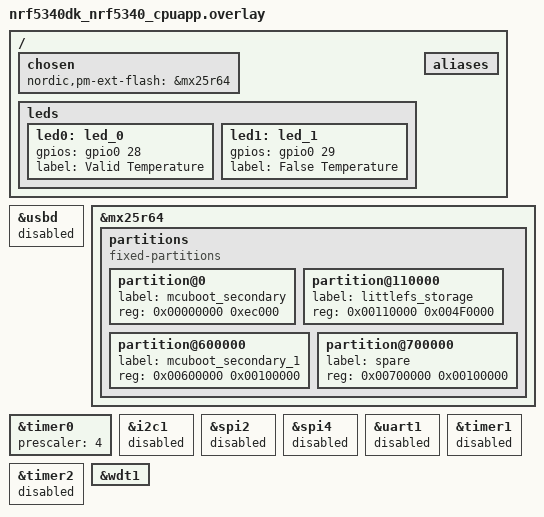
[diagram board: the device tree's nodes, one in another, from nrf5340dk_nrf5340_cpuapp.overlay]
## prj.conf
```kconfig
# Increased stack due to settings API usage
CONFIG_SYSTEM_WORKQUEUE_STACK_SIZE=2048

CONFIG_BT=y
CONFIG_BT_DEBUG_LOG=y
CONFIG_BT_SMP=y
CONFIG_BT_SIGNING=y
CONFIG_BT_PERIPHERAL=y
CONFIG_BT_DIS=y
CONFIG_BT_ATT_PREPARE_COUNT=5
CONFIG_BT_BAS=y
CONFIG_BT_HRS=y
CONFIG_BT_IAS=y
CONFIG_BT_PRIVACY=y
CONFIG_BT_DEVICE_NAME="Zephyr Peripheral Sample Long Name"
CONFIG_BT_DEVICE_APPEARANCE=833
CONFIG_BT_DEVICE_NAME_DYNAMIC=y
CONFIG_BT_DEVICE_NAME_MAX=65

CONFIG_BT_KEYS_OVERWRITE_OLDEST=y
# CONFIG_BT_SETTINGS=y
CONFIG_FLASH=y
CONFIG_FLASH_MAP=y
CONFIG_FLASH_PAGE_LAYOUT=y

CONFIG_FILE_SYSTEM=y
CONFIG_FILE_SYSTEM_LITTLEFS=y
CONFIG_NVS=y
# CONFIG_SETTINGS=y

# Enable bonding of Bluetooth peers.
# CONFIG_SETTINGS_FS_FILE="/lfs/bt/settings"
# CONFIG_SETTINGS_FS_DIR="/lfs/bt"

CONFIG_BT_HCI_VS=y                          # Vendor-specific commands
CONFIG_BT_HCI_VS_EXT=y                      # Extended vendor-specific

CONFIG_NORDIC_QSPI_NOR=y
CONFIG_NORDIC_QSPI_NOR_FLASH_LAYOUT_PAGE_SIZE=4096
CONFIG_NORDIC_QSPI_NOR_STACK_WRITE_BUFFER_SIZE=4
#CONFIG_PM_EXTERNAL_FLASH=y
#CONFIG_PM_EXTERNAL_FLASH_DEV_NAME="MX25R64"
#CONFIG_PM_EXTERNAL_FLASH_BASE=0x0
#CONFIG_PM_EXTERNAL_FLASH_SIZE=0x800000
#CONFIG_SPI_NOR_IDLE_IN_DPD=y

#CONFIG_NVS=y
CONFIG_MPU_ALLOW_FLASH_WRITE=y

#https://devzone.nordicsemi.com/f/nordic-q-a/76585/extends-the-mtu-size-in-latest-zephyr
CONFIG_BT_L2CAP_TX_MTU=498
CONFIG_BT_BUF_ACL_RX_SIZE=502
CONFIG_BT_BUF_ACL_TX_SIZE=502
CONFIG_BT_CTLR_DATA_LENGTH_MAX=251

CONFIG_BT_PERIPHERAL_PREF_MIN_INT=50
CONFIG_BT_PERIPHERAL_PREF_MAX_INT=250
CONFIG_BT_PERIPHERAL_PREF_LATENCY=0
CONFIG_BT_PERIPHERAL_PREF_TIMEOUT=600

# Appearance indicates the type of device (phone, computer, thermometer, etc).
# Set it to "Energy Harvesting Switch" 0x04CB (1227)
# https://specificationrefs.bluetooth.com/assigned-values/Appearance%20Values.pdf
CONFIG_BT_DEVICE_APPEARANCE=1227

# Configure the cryptography backends to use.
# WARNING: Don't turn this on!  It consumes >150ms of startup time!  Why?!?
#CONFIG_NORDIC_SECURITY_BACKEND=y
#CONFIG_CC3XX_BACKEND=y
##CONFIG_MBEDTLS_VANILLA_BACKEND=n
#CONFIG_OBERON_BACKEND=n

# Enable MCUboot and MCUmgr to support DFU firmware updates.
CONFIG_BOOTLOADER_MCUBOOT=y
CONFIG_MCUMGR=y
CONFIG_MCUMGR_CMD_IMG_MGMT=y
CONFIG_MCUMGR_CMD_OS_MGMT=y
CONFIG_MCUMGR_CMD_STAT_MGMT=y
CONFIG_MCUMGR_SMP_BT=y
#CONFIG_LOG=y
#CONFIG_MCUBOOT_UTIL_LOG_LEVEL_WRN=y
#CONFIG_LOG_DEFAULT_LEVEL=4

# From Overlay.bt-conf file
# Allow for large Bluetooth data packets.
# Enable the Bluetooth mcumgr transport (unauthenticated).
CONFIG_MCUMGR_SMP_BT_AUTHEN=n
CONFIG_MCUMGR_SMP_BT_CONN_PARAM_CONTROL=y

# Enable the mcumgr Packet Reassembly feature over Bluetooth and its configuration dependencies.
# MCUmgr buffer size is optimized to fit one SMP packet divided into five Bluetooth Write Commands,
# transmitted with the maximum possible MTU value: 498 bytes.
CONFIG_MCUMGR_SMP_REASSEMBLY_BT=y
CONFIG_MCUMGR_BUF_SIZE=2475
CONFIG_OS_MGMT_MCUMGR_PARAMS=y
# Enable file system commands
CONFIG_MCUMGR_CMD_FS_MGMT=y
# Enable the storage erase command.
CONFIG_MCUMGR_GRP_ZEPHYR_BASIC=y
CONFIG_MCUMGR_GRP_BASIC_CMD_STORAGE_ERASE=y
# Erase slot 1 in parts as and when FW is copied.
CONFIG_IMG_ERASE_PROGRESSIVELY=y
# Disable Bluetooth ping support
CONFIG_BT_CTLR_LE_PING=n

# The following configurations are required to support simultaneous multi image update
CONFIG_PCD_APP=y
CONFIG_UPDATEABLE_IMAGE_NUMBER=2
# CONFIG_BOOT_UPGRADE_ONLY=y
CONFIG_BT_RPMSG=y
```

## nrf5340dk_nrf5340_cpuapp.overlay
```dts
/* Shift the console to USB - FIXME: remove this later */
/*
/ {
    chosen {
        zephyr,console = &cdc_acm_uart0;
    };
};
&zephyr_udc0 {
        cdc_acm_uart0: cdc_acm_uart0 {
                compatible = "zephyr,cdc-acm-uart";
                label = "CDC_ACM_0";
        };
};*/
&usbd {
    status = "disabled";
};

/* Define the partitions in the external NOR flash memory chip */
&mx25r64 {

    partitions {
        compatible = "fixed-partitions";
        #address-cells = <1>;
        #size-cells = <1>;

        /* First 1Mb is for a second program image for MCUboot */
        partition@0 {
            label = "mcuboot_secondary";
            reg = <0x00000000 0xec000>;
        };


        /* 5056kB partition for the littlefs filesystem */
        partition@110000 {
            label = "littlefs_storage";
            reg = <0x00110000 0x004F0000>;
        };

        /* 1024kB spare partition */
        partition@600000 {
            label = "mcuboot_secondary_1";
            reg = <0x00600000 0x00100000>;
        };

        /* 1024kB spare partition */
        partition@700000 {
            label = "spare";
            reg = <0x00700000 0x00100000>;
        };
    };

};


/* Change the prescaler for timer0 so that it operates off the
   lower power 1MHz clock instead of the 16MHz clock. */
&timer0 {
    prescaler = <4>; /* prescaler of 2^4 = divide by 16 */
};

/* Disable peripherals that we don't need */
&i2c1 {
    status = "disabled";
};
&spi2 {
    status = "disabled";
};
&spi4 {
    status = "disabled";
    /delete-property/ cs-gpios;
};
&uart1 {
    status = "disabled";
};
&timer1 {
    status = "disabled";
};
&timer2 {
    status = "disabled";
};
&wdt1 {
    status = "okay";
};
/* Disable forwarding of UART pins to the network core */
/delete-node/ &gpio_fwd;

/ {
    /* Use paritition manager to manage the layout of external NOR flash */
    chosen {
        nordic,pm-ext-flash = &mx25r64;
    };

    /* Redefine the LED's */
    leds {
        /delete-node/ led0;
        /delete-node/ led1;

        led0: led_0 {
                gpios = <&gpio0 28 GPIO_ACTIVE_HIGH>;
                label = "Valid Temperature";
        };
        led1: led_1 {
                gpios = <&gpio0 29 GPIO_ACTIVE_HIGH>;
                label = "False Temperature";
        };
    };

    aliases {
        /* Remove unnecessary aliases */
        /delete-property/ led2;
        /delete-property/ led3;
        /delete-property/ sw0;
        /delete-property/ sw1;
        /delete-property/ sw2;
        /delete-property/ sw3;
        /delete-property/ pwm-led0;
    };

};
```

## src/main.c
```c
/* main.c - Application main entry point */

/*
 * Copyright (c) 2015-2016 Intel Corporation
 *
 * SPDX-License-Identifier: Apache-2.0
 */

#include <zephyr/types.h>
#include <stddef.h>
#include <string.h>
#include <errno.h>
#include <zephyr/sys/printk.h>
#include <zephyr/sys/byteorder.h>
#include <zephyr/kernel.h>

#include <zephyr/settings/settings.h>

#include <zephyr/bluetooth/bluetooth.h>
#include <zephyr/bluetooth/hci.h>
#include <zephyr/bluetooth/conn.h>
#include <zephyr/bluetooth/uuid.h>
#include <zephyr/bluetooth/gatt.h>
#include <zephyr/bluetooth/services/bas.h>
#include <zephyr/bluetooth/services/hrs.h>
#include <zephyr/bluetooth/services/ias.h>

#include <zephyr/mgmt/mcumgr/smp_bt.h>
#if defined(CONFIG_BT_HCI_VS_EXT)
#include <zephyr/bluetooth/bluetooth.h>
#include <zephyr/bluetooth/hci.h>
#include <zephyr/bluetooth/hci_vs.h>
#endif
// #include "filesystem.h"
#include "cts.h"
// #include "filesystem.h"
#ifdef CONFIG_MCUMGR_CMD_OS_MGMT
#include "os_mgmt/os_mgmt.h"
#endif
#ifdef CONFIG_MCUMGR_CMD_IMG_MGMT
#include "img_mgmt/img_mgmt.h"
#endif
#ifdef CONFIG_MCUMGR_CMD_STAT_MGMT
#include "stat_mgmt/stat_mgmt.h"
#endif
#ifdef CONFIG_MCUMGR_CMD_SHELL_MGMT
#include "shell_mgmt/shell_mgmt.h"
#endif

/* Custom Service Variables */
#define BT_UUID_CUSTOM_SERVICE_VAL \
	BT_UUID_128_ENCODE(0x12345678, 0x1234, 0x5678, 0x1234, 0x56789abcdef0)

static struct bt_uuid_128 vnd_uuid = BT_UUID_INIT_128(
	BT_UUID_CUSTOM_SERVICE_VAL);

static struct bt_uuid_128 vnd_enc_uuid = BT_UUID_INIT_128(
	BT_UUID_128_ENCODE(0x12345678, 0x1234, 0x5678, 0x1234, 0x56789abcdef1));

static struct bt_uuid_128 vnd_auth_uuid = BT_UUID_INIT_128(
	BT_UUID_128_ENCODE(0x12345678, 0x1234, 0x5678, 0x1234, 0x56789abcdef2));

#define VND_MAX_LEN 20

static uint8_t vnd_value[VND_MAX_LEN + 1] = { 'V', 'e', 'n', 'd', 'o', 'r'};
static uint8_t vnd_auth_value[VND_MAX_LEN + 1] = { 'V', 'e', 'n', 'd', 'o', 'r'};
static uint8_t vnd_wwr_value[VND_MAX_LEN + 1] = { 'V', 'e', 'n', 'd', 'o', 'r' };

static ssize_t read_vnd(struct bt_conn *conn, const struct bt_gatt_attr *attr,
			void *buf, uint16_t len, uint16_t offset)
{
	const char *value = attr->user_data;

	return bt_gatt_attr_read(conn, attr, buf, len, offset, value,
				 strlen(value));
}

static ssize_t write_vnd(struct bt_conn *conn, const struct bt_gatt_attr *attr,
			 const void *buf, uint16_t len, uint16_t offset,
			 uint8_t flags)
{
	uint8_t *value = attr->user_data;

	if (offset + len > VND_MAX_LEN) {
		return BT_GATT_ERR(BT_ATT_ERR_INVALID_OFFSET);
	}

	memcpy(value + offset, buf, len);
	value[offset + len] = 0;

	return len;
}

static uint8_t simulate_vnd;
static uint8_t indicating;
static struct bt_gatt_indicate_params ind_params;

static void vnd_ccc_cfg_changed(const struct bt_gatt_attr *attr, uint16_t value)
{
	simulate_vnd = (value == BT_GATT_CCC_INDICATE) ? 1 : 0;
}

static void indicate_cb(struct bt_conn *conn,
			struct bt_gatt_indicate_params *params, uint8_t err)
{
	printk("Indication %s\n", err != 0U ? "fail" : "success");
}

static void indicate_destroy(struct bt_gatt_indicate_params *params)
{
	printk("Indication complete\n");
	indicating = 0U;
}

#define VND_LONG_MAX_LEN 74
static uint8_t vnd_long_value[VND_LONG_MAX_LEN + 1] = {
		  'V', 'e', 'n', 'd', 'o', 'r', ' ', 'd', 'a', 't', 'a', '1',
		  'V', 'e', 'n', 'd', 'o', 'r', ' ', 'd', 'a', 't', 'a', '2',
		  'V', 'e', 'n', 'd', 'o', 'r', ' ', 'd', 'a', 't', 'a', '3',
		  'V', 'e', 'n', 'd', 'o', 'r', ' ', 'd', 'a', 't', 'a', '4',
		  'V', 'e', 'n', 'd', 'o', 'r', ' ', 'd', 'a', 't', 'a', '5',
		  'V', 'e', 'n', 'd', 'o', 'r', ' ', 'd', 'a', 't', 'a', '6',
		  '.', ' ' };

static ssize_t write_long_vnd(struct bt_conn *conn,
			      const struct bt_gatt_attr *attr, const void *buf,
			      uint16_t len, uint16_t offset, uint8_t flags)
{
	uint8_t *value = attr->user_data;

	if (flags & BT_GATT_WRITE_FLAG_PREPARE) {
		return 0;
	}

	if (offset + len > VND_LONG_MAX_LEN) {
		return BT_GATT_ERR(BT_ATT_ERR_INVALID_OFFSET);
	}

	memcpy(value + offset, buf, len);
	value[offset + len] = 0;

	return len;
}

static const struct bt_uuid_128 vnd_long_uuid = BT_UUID_INIT_128(
	BT_UUID_128_ENCODE(0x12345678, 0x1234, 0x5678, 0x1234, 0x56789abcdef3));

static struct bt_gatt_cep vnd_long_cep = {
	.properties = BT_GATT_CEP_RELIABLE_WRITE,
};

static int signed_value;

static ssize_t read_signed(struct bt_conn *conn, const struct bt_gatt_attr *attr,
			   void *buf, uint16_t len, uint16_t offset)
{
	const char *value = attr->user_data;

	return bt_gatt_attr_read(conn, attr, buf, len, offset, value,
				 sizeof(signed_value));
}

static ssize_t write_signed(struct bt_conn *conn, const struct bt_gatt_attr *attr,
			    const void *buf, uint16_t len, uint16_t offset,
			    uint8_t flags)
{
	uint8_t *value = attr->user_data;

	if (offset + len > sizeof(signed_value)) {
		return BT_GATT_ERR(BT_ATT_ERR_INVALID_OFFSET);
	}

	memcpy(value + offset, buf, len);

	return len;
}

static const struct bt_uuid_128 vnd_signed_uuid = BT_UUID_INIT_128(
	BT_UUID_128_ENCODE(0x13345678, 0x1234, 0x5678, 0x1334, 0x56789abcdef3));

static const struct bt_uuid_128 vnd_write_cmd_uuid = BT_UUID_INIT_128(
	BT_UUID_128_ENCODE(0x12345678, 0x1234, 0x5678, 0x1234, 0x56789abcdef4));

static ssize_t write_without_rsp_vnd(struct bt_conn *conn,
				     const struct bt_gatt_attr *attr,
				     const void *buf, uint16_t len, uint16_t offset,
				     uint8_t flags)
{
	uint8_t *value = attr->user_data;

	if (!(flags & BT_GATT_WRITE_FLAG_CMD)) {
		/* Write Request received. Reject it since this Characteristic
		 * only accepts Write Without Response.
		 */
		return BT_GATT_ERR(BT_ATT_ERR_WRITE_REQ_REJECTED);
	}

	if (offset + len > VND_MAX_LEN) {
		return BT_GATT_ERR(BT_ATT_ERR_INVALID_OFFSET);
	}

	memcpy(value + offset, buf, len);
	value[offset + len] = 0;

	return len;
}

/* Vendor Primary Service Declaration */
BT_GATT_SERVICE_DEFINE(vnd_svc,
	BT_GATT_PRIMARY_SERVICE(&vnd_uuid),
	BT_GATT_CHARACTERISTIC(&vnd_enc_uuid.uuid,
			       BT_GATT_CHRC_READ | BT_GATT_CHRC_WRITE |
			       BT_GATT_CHRC_INDICATE,
			       BT_GATT_PERM_READ_ENCRYPT |
			       BT_GATT_PERM_WRITE_ENCRYPT,
			       read_vnd, write_vnd, vnd_value),
	BT_GATT_CCC(vnd_ccc_cfg_changed,
		    BT_GATT_PERM_READ | BT_GATT_PERM_WRITE_ENCRYPT),
	BT_GATT_CHARACTERISTIC(&vnd_auth_uuid.uuid,
			       BT_GATT_CHRC_READ | BT_GATT_CHRC_WRITE,
			       BT_GATT_PERM_READ_AUTHEN |
			       BT_GATT_PERM_WRITE_AUTHEN,
			       read_vnd, write_vnd, vnd_auth_value),
	BT_GATT_CHARACTERISTIC(&vnd_long_uuid.uuid, BT_GATT_CHRC_READ |
			       BT_GATT_CHRC_WRITE | BT_GATT_CHRC_EXT_PROP,
			       BT_GATT_PERM_READ | BT_GATT_PERM_WRITE |
			       BT_GATT_PERM_PREPARE_WRITE,
			       read_vnd, write_long_vnd, &vnd_long_value),
	BT_GATT_CEP(&vnd_long_cep),
	BT_GATT_CHARACTERISTIC(&vnd_signed_uuid.uuid, BT_GATT_CHRC_READ |
			       BT_GATT_CHRC_WRITE | BT_GATT_CHRC_AUTH,
			       BT_GATT_PERM_READ | BT_GATT_PERM_WRITE,
			       read_signed, write_signed, &signed_value),
	BT_GATT_CHARACTERISTIC(&vnd_write_cmd_uuid.uuid,
			       BT_GATT_CHRC_WRITE_WITHOUT_RESP,
			       BT_GATT_PERM_WRITE, NULL,
			       write_without_rsp_vnd, &vnd_wwr_value),
);

static const struct bt_data ad[] = {
	BT_DATA_BYTES(BT_DATA_FLAGS, (BT_LE_AD_GENERAL | BT_LE_AD_NO_BREDR)),
	BT_DATA_BYTES(BT_DATA_UUID16_ALL,
		      BT_UUID_16_ENCODE(BT_UUID_HRS_VAL),
		      BT_UUID_16_ENCODE(BT_UUID_BAS_VAL),
		      BT_UUID_16_ENCODE(BT_UUID_CTS_VAL)),
	BT_DATA_BYTES(BT_DATA_UUID128_ALL, BT_UUID_CUSTOM_SERVICE_VAL),
};

void mtu_updated(struct bt_conn *conn, uint16_t tx, uint16_t rx)
{
	printk("Updated MTU: TX: %d RX: %d bytes\n", tx, rx);
}

static struct bt_gatt_cb gatt_callbacks = {
	.att_mtu_updated = mtu_updated
};

static void connected(struct bt_conn *conn, uint8_t err)
{
	if (err) {
		printk("Connection failed (err 0x%02x)\n", err);
	} else {
		printk("Connected\n");
	}
}

static void disconnected(struct bt_conn *conn, uint8_t reason)
{
	printk("Disconnected (reason 0x%02x)\n", reason);
}

static void alert_stop(void)
{
	printk("Alert stopped\n");
}

static void alert_start(void)
{
	printk("Mild alert started\n");
}

static void alert_high_start(void)
{
	printk("High alert started\n");
}

BT_CONN_CB_DEFINE(conn_callbacks) = {
	.connected = connected,
	.disconnected = disconnected,
};

BT_IAS_CB_DEFINE(ias_callbacks) = {
	.no_alert = alert_stop,
	.mild_alert = alert_start,
	.high_alert = alert_high_start,
};

static void bt_ready(void)
{
	int err;

	printk("Bluetooth initialized\n");

	cts_init();

	if (IS_ENABLED(CONFIG_SETTINGS)) {
		settings_load();
	}

	err = bt_le_adv_start(BT_LE_ADV_CONN_NAME, ad, ARRAY_SIZE(ad), NULL, 0);
	if (err) {
		printk("Advertising failed to start (err %d)\n", err);
		return;
	}

	printk("Advertising successfully started\n");
}

static void auth_passkey_display(struct bt_conn *conn, unsigned int passkey)
{
	char addr[BT_ADDR_LE_STR_LEN];

	bt_addr_le_to_str(bt_conn_get_dst(conn), addr, sizeof(addr));

	printk("Passkey for %s: %06u\n", addr, passkey);
}

static void auth_cancel(struct bt_conn *conn)
{
	char addr[BT_ADDR_LE_STR_LEN];

	bt_addr_le_to_str(bt_conn_get_dst(conn), addr, sizeof(addr));

	printk("Pairing cancelled: %s\n", addr);
}

static struct bt_conn_auth_cb auth_cb_display = {
	.passkey_display = auth_passkey_display,
	.passkey_entry = NULL,
	.cancel = auth_cancel,
};

static void bas_notify(void)
{
	uint8_t battery_level = bt_bas_get_battery_level();

	battery_level--;

	if (!battery_level) {
		battery_level = 100U;
	}

	bt_bas_set_battery_level(battery_level);
}

static void hrs_notify(void)
{
	static uint8_t heartrate = 90U;

	/* Heartrate measurements simulation */
	heartrate++;
	if (heartrate == 160U) {
		heartrate = 90U;
	}

	bt_hrs_notify(heartrate);
}

static int readTemperature(void)
{
    int temp;
#if defined(CONFIG_BT_HCI_VS_EXT)
    struct net_buf *response = 0;
    const struct bt_hci_rp_vs_read_chip_temp *data;
    if (bt_hci_cmd_send_sync
            (BT_HCI_OP_VS_READ_CHIP_TEMP, NULL, &response) != 0) {
        // Request to the network core failed for some reason.
        return -100;
    }
    data = (const struct bt_hci_rp_vs_read_chip_temp *)(response->data);
    if (data->status == 0)
        temp = data->temps;
    else
        temp = -100;
    net_buf_unref(response);
#else
    temp = DEG_C(-100);
#endif
    return temp;
}

void start_smp_bluetooth(void)
{
	/* Initialize the Bluetooth mcumgr transport. */
	printk("SMP BT Reg %d \r\n",smp_bt_register());
}

void main(void)
{
	struct bt_gatt_attr *vnd_ind_attr;
	char str[BT_UUID_STR_LEN];
	int err;

	// FS_Mount();
	// if (IS_ENABLED(CONFIG_SETTINGS)) {
	// 	settings_load();
	// }

	err = bt_enable(NULL);
	if (err) {
		printk("Bluetooth init failed (err %d)\n", err);
		return;
	}

	bt_ready();

	bt_gatt_cb_register(&gatt_callbacks);
	bt_conn_auth_cb_register(&auth_cb_display);

	vnd_ind_attr = bt_gatt_find_by_uuid(vnd_svc.attrs, vnd_svc.attr_count,
					    &vnd_enc_uuid.uuid);
	bt_uuid_to_str(&vnd_enc_uuid.uuid, str, sizeof(str));
	printk("Indicate VND attr %p (UUID %s)\n", vnd_ind_attr, str);

	/* Implement notification. At the moment there is no suitable way
	 * of starting delayed work so we do it here
	 */

#ifdef CONFIG_MCUMGR_CMD_OS_MGMT
	os_mgmt_register_group();
#endif
#ifdef CONFIG_MCUMGR_CMD_IMG_MGMT
	img_mgmt_register_group();
#endif
#ifdef CONFIG_MCUMGR_CMD_STAT_MGMT
	stat_mgmt_register_group();
#endif
#ifdef CONFIG_MCUMGR_CMD_SHELL_MGMT
	shell_mgmt_register_group();
#endif
#ifdef CONFIG_MCUMGR_SMP_BT
	start_smp_bluetooth();
#endif

	while (1) {

		printk("Temperature %d C\r\n", readTemperature());
		k_sleep(K_SECONDS(5));

		/* Current Time Service updates only when time is changed */
		cts_notify();

		/* Heartrate measurements simulation */
		hrs_notify();

		/* Battery level simulation */
		bas_notify();

		/* Vendor indication simulation */
		if (simulate_vnd && vnd_ind_attr) {
			if (indicating) {
				continue;
			}

			ind_params.attr = vnd_ind_attr;
			ind_params.func = indicate_cb;
			ind_params.destroy = indicate_destroy;
			ind_params.data = &indicating;
			ind_params.len = sizeof(indicating);

			if (bt_gatt_indicate(NULL, &ind_params) == 0) {
				indicating = 1U;
			}
		}
	}
}
```
